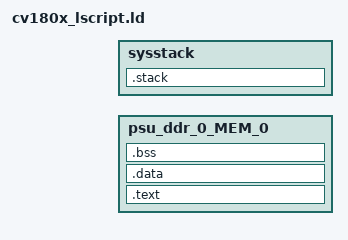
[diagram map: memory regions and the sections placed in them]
/*******************************************************************/
/*                                                                 */
/* This file is automatically generated by linker script generator.*/
/*                                                                 */
/* Version:                                 */
/*                                                                 */
/* Copyright (c) 2010-2016 Xilinx, Inc.  All rights reserved.      */
/*                                                                 */
/* Description : Cortex-A53 Linker Script                          */
/*                                                                 */
/*******************************************************************/
INCLUDE cvi_board_memmap.ld

_STACK_SIZE = DEFINED(_STACK_SIZE) ? _STACK_SIZE : 0x1000;


MEMORY
{
   psu_ddr_0_MEM_0 : ORIGIN = CVIMMAP_FREERTOS_ADDR , LENGTH = CVIMMAP_FREERTOS_SIZE - _STACK_SIZE
   sysstack	   : ORIGIN = CVIMMAP_FREERTOS_ADDR + CVIMMAP_FREERTOS_SIZE - _STACK_SIZE, LENGTH = _STACK_SIZE
}

/* Specify the default entry point to the program */

/*ENTRY(_vector_table)*/
ENTRY(_start)

/* Define the sections, and where they are mapped in memory */

SECTIONS
{
.text : {
   KEEP (*(.vectors))
   *(.text)
   *(.text.*)
   __rodata_start = .;
   *(.rodata)
   *(.rodata.*)
   *(.srodata)
   *(.srodata.*)
   __rodata_end = .;
} > psu_ddr_0_MEM_0


.data : {
   . = ALIGN(16);
   _data = .;
   __data_start = .;
   *(.sdata)
   *(.sdata.*)
   *(.data)
   *(.data.*)
   __data_end = .;
  _edata = .;
} > psu_ddr_0_MEM_0

.bss (NOLOAD) : {
   . = ALIGN(16);
   __bss_start__ = .;
   _bss = .;
   *(.bss)
   *(.bss.*)
   *(.sbss)
   *(.sbss.*)
   _ebss = .;
   __bss_end__ = .;
} > psu_ddr_0_MEM_0

/*_SDA_BASE_ = __sdata_start + ((__sbss_end - __sdata_start) / 2 );*/
    _data_lma = LOADADDR(.data);

/* Generate Stack and Heap definitions */
.stack (NOLOAD) : {
   . = ALIGN(16);
   _stack_end_end = .;
   . += _STACK_SIZE;
   _stack_top = .;
} > sysstack

_end = .;


}

